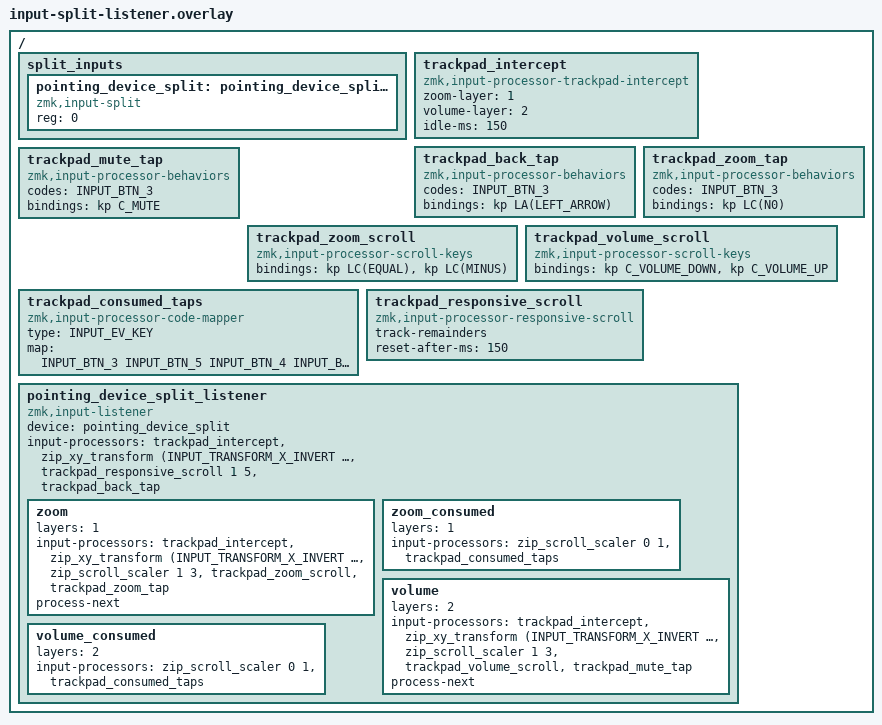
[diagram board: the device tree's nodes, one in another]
#include <dt-bindings/zmk/keys.h>
#include <zephyr/dt-bindings/input/input-event-codes.h>

/ {
    split_inputs {
        #address-cells = <1>;
        #size-cells = <0>;

        pointing_device_split: pointing_device_split@0 {
            compatible = "zmk,input-split";
            reg = <0>;
        };
    };

    trackpad_intercept: trackpad_intercept {
        compatible = "zmk,input-processor-trackpad-intercept";
        #input-processor-cells = <0>;
        zoom-layer = <1>;
        volume-layer = <2>;
        idle-ms = <150>;
    };

    trackpad_back_tap: trackpad_back_tap {
        compatible = "zmk,input-processor-behaviors";
        #input-processor-cells = <0>;
        codes = <INPUT_BTN_3>;
        bindings = <&kp LA(LEFT_ARROW)>;
    };

    trackpad_zoom_tap: trackpad_zoom_tap {
        compatible = "zmk,input-processor-behaviors";
        #input-processor-cells = <0>;
        codes = <INPUT_BTN_3>;
        bindings = <&kp LC(N0)>;
    };

    trackpad_mute_tap: trackpad_mute_tap {
        compatible = "zmk,input-processor-behaviors";
        #input-processor-cells = <0>;
        codes = <INPUT_BTN_3>;
        bindings = <&kp C_MUTE>;
    };

    // Positive wheel step first, negative wheel step second.
    trackpad_zoom_scroll: trackpad_zoom_scroll {
        compatible = "zmk,input-processor-scroll-keys";
        #input-processor-cells = <0>;
        bindings = <&kp LC(EQUAL) &kp LC(MINUS)>;
    };

    trackpad_volume_scroll: trackpad_volume_scroll {
        compatible = "zmk,input-processor-scroll-keys";
        #input-processor-cells = <0>;
        bindings = <&kp C_VOLUME_DOWN &kp C_VOLUME_UP>;
    };

    // ZMK v0.3 passes STOP from a layer override through to HID. Remap used tap
    // buttons to a code the mouse listener ignores after the shortcut fires.
    trackpad_consumed_taps: trackpad_consumed_taps {
        compatible = "zmk,input-processor-code-mapper";
        #input-processor-cells = <0>;
        type = <INPUT_EV_KEY>;
        map = <INPUT_BTN_3 INPUT_BTN_5 INPUT_BTN_4 INPUT_BTN_5>;
    };

    trackpad_responsive_scroll: trackpad_responsive_scroll {
        compatible = "zmk,input-processor-responsive-scroll";
        #input-processor-cells = <2>;
        track-remainders;
        reset-after-ms = <150>;
    };

    pointing_device_split_listener: pointing_device_split_listener {
        compatible = "zmk,input-listener";
        device = <&pointing_device_split>;
        status = "okay";
        input-processors = <
            &trackpad_intercept
            &zip_xy_transform (INPUT_TRANSFORM_X_INVERT | INPUT_TRANSFORM_Y_INVERT)
            &trackpad_responsive_scroll 1 5
            &trackpad_back_tap
        >;

        zoom {
            layers = <1>;
            input-processors = <
                &trackpad_intercept
                &zip_xy_transform (INPUT_TRANSFORM_X_INVERT | INPUT_TRANSFORM_Y_INVERT)
                &zip_scroll_scaler 1 3
                &trackpad_zoom_scroll
                &trackpad_zoom_tap
            >;
            process-next;
        };

        zoom_consumed {
            layers = <1>;
            input-processors = <
                &zip_scroll_scaler 0 1
                &trackpad_consumed_taps
            >;
        };

        volume {
            layers = <2>;
            input-processors = <
                &trackpad_intercept
                &zip_xy_transform (INPUT_TRANSFORM_X_INVERT | INPUT_TRANSFORM_Y_INVERT)
                &zip_scroll_scaler 1 3
                &trackpad_volume_scroll
                &trackpad_mute_tap
            >;
            process-next;
        };

        volume_consumed {
            layers = <2>;
            input-processors = <
                &zip_scroll_scaler 0 1
                &trackpad_consumed_taps
            >;
        };
    };
};
